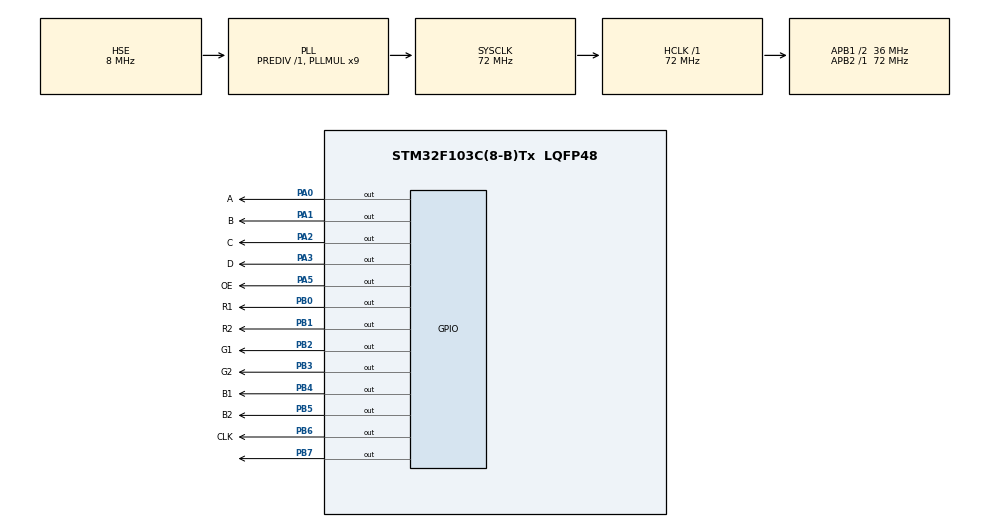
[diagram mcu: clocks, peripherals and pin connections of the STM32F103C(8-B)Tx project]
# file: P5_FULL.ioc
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Mcu.Family=STM32F1
Mcu.Name=STM32F103C(8-B)Tx
Mcu.Package=LQFP48
NVIC.PriorityGroup=NVIC_PRIORITYGROUP_4
NVIC.TIM1_UP_IRQn=true\:0\:0\:false\:false\:true\:true
PA0-WKUP.GPIO_Label=A
PA0-WKUP.GPIO_Speed=GPIO_SPEED_FREQ_HIGH
PA0-WKUP.PinState=GPIO_PIN_SET
PA0-WKUP.Signal=GPIO_Output
PA1.GPIO_Label=B
PA1.GPIO_Speed=GPIO_SPEED_FREQ_HIGH
PA1.PinState=GPIO_PIN_SET
PA1.Signal=GPIO_Output
PA13.Mode=Serial_Wire
PA13.Signal=SYS_JTMS-SWDIO
PA14.Mode=Serial_Wire
PA14.Signal=SYS_JTCK-SWCLK
PA2.GPIO_Label=C
PA2.GPIO_Speed=GPIO_SPEED_FREQ_HIGH
PA2.PinState=GPIO_PIN_SET
PA2.Signal=GPIO_Output
PA3.GPIO_Label=D
PA3.GPIO_Speed=GPIO_SPEED_FREQ_HIGH
PA3.PinState=GPIO_PIN_SET
PA3.Signal=GPIO_Output
PA5.GPIO_Label=OE
PA5.GPIO_Speed=GPIO_SPEED_FREQ_HIGH
PA5.PinState=GPIO_PIN_SET
PA5.Signal=GPIO_Output
PB0.GPIO_Label=R1
PB0.GPIO_Speed=GPIO_SPEED_FREQ_HIGH
PB0.PinState=GPIO_PIN_SET
PB0.Signal=GPIO_Output
PB1.GPIO_Label=R2
PB1.GPIO_Speed=GPIO_SPEED_FREQ_HIGH
PB1.PinState=GPIO_PIN_SET
PB1.Signal=GPIO_Output
PB2.GPIO_Label=G1
PB2.GPIO_Speed=GPIO_SPEED_FREQ_HIGH
PB2.PinState=GPIO_PIN_SET
PB2.Signal=GPIO_Output
PB3.GPIO_Label=G2
PB3.GPIO_Speed=GPIO_SPEED_FREQ_HIGH
PB3.PinState=GPIO_PIN_SET
PB3.Signal=GPIO_Output
PB4.GPIO_Label=B1
PB4.GPIO_Speed=GPIO_SPEED_FREQ_HIGH
PB4.PinState=GPIO_PIN_SET
PB4.Signal=GPIO_Output
PB5.GPIO_Label=B2
PB5.GPIO_Speed=GPIO_SPEED_FREQ_HIGH
PB5.PinState=GPIO_PIN_SET
PB5.Signal=GPIO_Output
PB6.GPIO_Label=CLK
PB6.GPIO_Speed=GPIO_SPEED_FREQ_HIGH
PB6.PinState=GPIO_PIN_SET
PB6.Signal=GPIO_Output
PB7.GPIO_Speed=GPIO_SPEED_FREQ_HIGH
PB7.PinState=GPIO_PIN_SET
PB7.Signal=GPIO_Output
PD0-OSC_IN.Mode=HSE-External-Oscillator
PD0-OSC_IN.Signal=RCC_OSC_IN
PD1-OSC_OUT.Mode=HSE-External-Oscillator
PD1-OSC_OUT.Signal=RCC_OSC_OUT
ProjectManager.HeapSize=0x200
ProjectManager.StackSize=0x400
ProjectManager.TargetToolchain=MDK-ARM V5
RCC.AHBFreq_Value=72000000
RCC.APB1CLKDivider=RCC_HCLK_DIV2
RCC.APB1Freq_Value=36000000
RCC.APB1TimFreq_Value=72000000
RCC.APB2Freq_Value=72000000
RCC.APB2TimFreq_Value=72000000
RCC.HCLKFreq_Value=72000000
RCC.PLLMUL=RCC_PLL_MUL9
RCC.PLLSourceVirtual=RCC_PLLSOURCE_HSE
RCC.SYSCLKFreq_VALUE=72000000
RCC.SYSCLKSource=RCC_SYSCLKSOURCE_PLLCLK
RCC.USBFreq_Value=72000000
TIM1.CounterMode=TIM_COUNTERMODE_DOWN
TIM1.Period=40
VP_TIM1_VS_ClockSourceINT.Mode=Internal
board=custom

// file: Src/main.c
/* USER CODE BEGIN Header */
/**
  ******************************************************************************
  * @file           : main.c
  * @brief          : Main program body
  ******************************************************************************
  ** This notice applies to any and all portions of this file
  * that are not between comment pairs USER CODE BEGIN and
  * USER CODE END. Other portions of this file, whether
  * inserted by the user or by software development tools
  * are owned by their respective copyright owners.
  *
  * COPYRIGHT(c) 2020 STMicroelectronics
  *
  * Redistribution and use in source and binary forms, with or without modification,
  * are permitted provided that the following conditions are met:
  *   1. Redistributions of source code must retain the above copyright notice,
  *      this list of conditions and the following disclaimer.
  *   2. Redistributions in binary form must reproduce the above copyright notice,
  *      this list of conditions and the following disclaimer in the documentation
  *      and/or other materials provided with the distribution.
  *   3. Neither the name of STMicroelectronics nor the names of its contributors
  *      may be used to endorse or promote products derived from this software
  *      without specific prior written permission.
  *
  * THIS SOFTWARE IS PROVIDED BY THE COPYRIGHT HOLDERS AND CONTRIBUTORS "AS IS"
  * AND ANY EXPRESS OR IMPLIED WARRANTIES, INCLUDING, BUT NOT LIMITED TO, THE
  * IMPLIED WARRANTIES OF MERCHANTABILITY AND FITNESS FOR A PARTICULAR PURPOSE ARE
  * DISCLAIMED. IN NO EVENT SHALL THE COPYRIGHT HOLDER OR CONTRIBUTORS BE LIABLE
  * FOR ANY DIRECT, INDIRECT, INCIDENTAL, SPECIAL, EXEMPLARY, OR CONSEQUENTIAL
  * DAMAGES (INCLUDING, BUT NOT LIMITED TO, PROCUREMENT OF SUBSTITUTE GOODS OR
  * SERVICES; LOSS OF USE, DATA, OR PROFITS; OR BUSINESS INTERRUPTION) HOWEVER
  * CAUSED AND ON ANY THEORY OF LIABILITY, WHETHER IN CONTRACT, STRICT LIABILITY,
  * OR TORT (INCLUDING NEGLIGENCE OR OTHERWISE) ARISING IN ANY WAY OUT OF THE USE
  * OF THIS SOFTWARE, EVEN IF ADVISED OF THE POSSIBILITY OF SUCH DAMAGE.
  *
  ******************************************************************************
  */
/* USER CODE END Header */

#include "main.h"

/* USER CODE BEGIN Includes */
#include "p5_fullmau.h"
#include "mario.h"
/* USER CODE END Includes */

TIM_HandleTypeDef htim1;

void SystemClock_Config(void);
static void MX_GPIO_Init(void);
static void MX_TIM1_Init(void);

int main(void)
{

  /* MCU Configuration--------------------------------------------------------*/

  /* Reset of all peripherals, Initializes the Flash interface and the Systick. */
  HAL_Init();

  /* Configure the system clock */
  SystemClock_Config();

  /* Initialize all configured peripherals */
  MX_GPIO_Init();
  MX_TIM1_Init();
  /* USER CODE BEGIN 2 */
	HAL_TIM_Base_Start_IT(&htim1);
	unsigned char maumang;
  /* USER CODE END 2 */

  /* Infinite loop */
  while (1)
  {

    /* USER CODE BEGIN 3 */
		MATRIX_putStr16x32(0,0,"DA2",0,maumang,0);
		drawImage(64,0,64,32,(uint16_t *)mario);
		maumang++;
		if(maumang==254) maumang=0;

		giaimap5fullmau();
		matrix_p5fullmau_clear_all();
  }
  /* USER CODE END 3 */
}

void SystemClock_Config(void)
{
  RCC_OscInitTypeDef RCC_OscInitStruct = {0};
  RCC_ClkInitTypeDef RCC_ClkInitStruct = {0};

  /**Initializes the CPU, AHB and APB busses clocks
  */
  RCC_OscInitStruct.OscillatorType = RCC_OSCILLATORTYPE_HSE;
  RCC_OscInitStruct.HSEState = RCC_HSE_ON;
  RCC_OscInitStruct.HSEPredivValue = RCC_HSE_PREDIV_DIV1;
  RCC_OscInitStruct.HSIState = RCC_HSI_ON;
  RCC_OscInitStruct.PLL.PLLState = RCC_PLL_ON;
  RCC_OscInitStruct.PLL.PLLSource = RCC_PLLSOURCE_HSE;
  RCC_OscInitStruct.PLL.PLLMUL = RCC_PLL_MUL9;
  if (HAL_RCC_OscConfig(&RCC_OscInitStruct) != HAL_OK)
  {
    Error_Handler();
  }
  /**Initializes the CPU, AHB and APB busses clocks
  */
  RCC_ClkInitStruct.ClockType = RCC_CLOCKTYPE_HCLK|RCC_CLOCKTYPE_SYSCLK
                              |RCC_CLOCKTYPE_PCLK1|RCC_CLOCKTYPE_PCLK2;
  RCC_ClkInitStruct.SYSCLKSource = RCC_SYSCLKSOURCE_PLLCLK;
  RCC_ClkInitStruct.AHBCLKDivider = RCC_SYSCLK_DIV1;
  RCC_ClkInitStruct.APB1CLKDivider = RCC_HCLK_DIV2;
  RCC_ClkInitStruct.APB2CLKDivider = RCC_HCLK_DIV1;

  if (HAL_RCC_ClockConfig(&RCC_ClkInitStruct, FLASH_LATENCY_2) != HAL_OK)
  {
    Error_Handler();
  }
}

static void MX_TIM1_Init(void)
{

  TIM_ClockConfigTypeDef sClockSourceConfig = {0};
  TIM_MasterConfigTypeDef sMasterConfig = {0};

  htim1.Instance = TIM1;
  htim1.Init.Prescaler = 5;
  htim1.Init.CounterMode = TIM_COUNTERMODE_DOWN;
  htim1.Init.Period = 40;
  htim1.Init.ClockDivision = TIM_CLOCKDIVISION_DIV1;
  htim1.Init.RepetitionCounter = 0;
  htim1.Init.AutoReloadPreload = TIM_AUTORELOAD_PRELOAD_DISABLE;
  if (HAL_TIM_Base_Init(&htim1) != HAL_OK)
  {
    Error_Handler();
  }
  sClockSourceConfig.ClockSource = TIM_CLOCKSOURCE_INTERNAL;
  if (HAL_TIM_ConfigClockSource(&htim1, &sClockSourceConfig) != HAL_OK)
  {
    Error_Handler();
  }
  sMasterConfig.MasterOutputTrigger = TIM_TRGO_RESET;
  sMasterConfig.MasterSlaveMode = TIM_MASTERSLAVEMODE_DISABLE;
  if (HAL_TIMEx_MasterConfigSynchronization(&htim1, &sMasterConfig) != HAL_OK)
  {
    Error_Handler();
  }

}

static void MX_GPIO_Init(void)
{
  GPIO_InitTypeDef GPIO_InitStruct = {0};

  /* GPIO Ports Clock Enable */
  __HAL_RCC_GPIOD_CLK_ENABLE();
  __HAL_RCC_GPIOA_CLK_ENABLE();
  __HAL_RCC_GPIOB_CLK_ENABLE();

  /*Configure GPIO pin Output Level */
  HAL_GPIO_WritePin(GPIOA, A_Pin|B_Pin|C_Pin|D_Pin
                          |OE_Pin, GPIO_PIN_SET);

  /*Configure GPIO pin Output Level */
  HAL_GPIO_WritePin(GPIOB, R1_Pin|R2_Pin|G1_Pin|G2_Pin
                          |B1_Pin|B2_Pin|CLK_Pin|GPIO_PIN_7, GPIO_PIN_SET);

  /*Configure GPIO pins : A_Pin B_Pin C_Pin D_Pin
                           OE_Pin */
  GPIO_InitStruct.Pin = A_Pin|B_Pin|C_Pin|D_Pin
                          |OE_Pin;
  GPIO_InitStruct.Mode = GPIO_MODE_OUTPUT_PP;
  GPIO_InitStruct.Pull = GPIO_NOPULL;
  GPIO_InitStruct.Speed = GPIO_SPEED_FREQ_HIGH;
  HAL_GPIO_Init(GPIOA, &GPIO_InitStruct);

  /*Configure GPIO pins : R1_Pin R2_Pin G1_Pin G2_Pin
                           B1_Pin B2_Pin CLK_Pin PB7 */
  GPIO_InitStruct.Pin = R1_Pin|R2_Pin|G1_Pin|G2_Pin
                          |B1_Pin|B2_Pin|CLK_Pin|GPIO_PIN_7;
  GPIO_InitStruct.Mode = GPIO_MODE_OUTPUT_PP;
  GPIO_InitStruct.Pull = GPIO_NOPULL;
  GPIO_InitStruct.Speed = GPIO_SPEED_FREQ_HIGH;
  HAL_GPIO_Init(GPIOB, &GPIO_InitStruct);

}

void Error_Handler(void)
{
}

/************************ (C) COPYRIGHT STMicroelectronics *****END OF FILE****/
